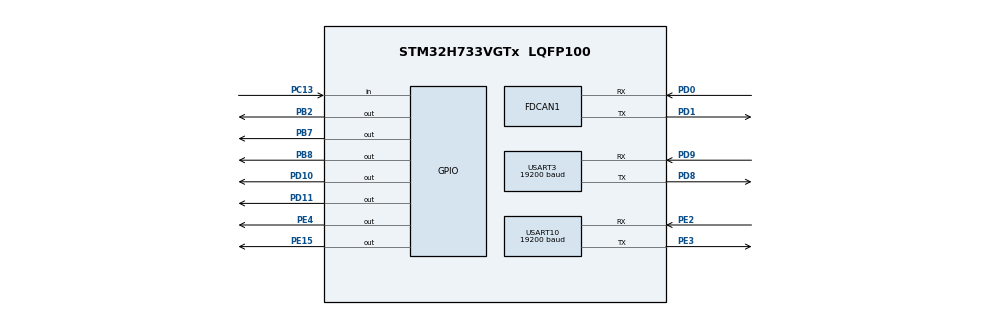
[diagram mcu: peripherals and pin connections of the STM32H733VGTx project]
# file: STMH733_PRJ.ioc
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FDCAN1.NominalPrescaler=6
FDCAN1.NominalTimeSeg1=6
FDCAN1.NominalTimeSeg2=7
Mcu.Family=STM32H7
Mcu.Name=STM32H733VGTx
Mcu.Package=LQFP100
NVIC.FDCAN1_IT0_IRQn=true\:0\:0\:false\:false\:true\:true\:true
NVIC.PriorityGroup=NVIC_PRIORITYGROUP_4
NVIC.TIM1_BRK_IRQn=true\:0\:0\:false\:false\:true\:true\:true
NVIC.TIM1_UP_IRQn=true\:0\:0\:true\:false\:true\:true\:true
NVIC.TIM2_IRQn=true\:0\:0\:false\:false\:true\:true\:true
NVIC.TIM3_IRQn=true\:0\:0\:false\:false\:true\:true\:true
NVIC.TIM8_UP_TIM13_IRQn=true\:0\:0\:false\:false\:true\:true\:true
NVIC.USART10_IRQn=true\:0\:0\:false\:false\:true\:true\:true
NVIC.USART3_IRQn=true\:0\:0\:false\:false\:true\:true\:true
PA13(JTMS/SWDIO).Mode=Serial_Wire
PA13(JTMS/SWDIO).Signal=DEBUG_JTMS-SWDIO
PA14(JTCK/SWCLK).Mode=Serial_Wire
PA14(JTCK/SWCLK).Signal=DEBUG_JTCK-SWCLK
PB2.GPIO_PuPd=GPIO_NOPULL
PB2.Signal=GPIO_Output
PB7.Signal=GPIO_Output
PB8.GPIO_PuPd=GPIO_NOPULL
PB8.Signal=GPIO_Output
PC13.Signal=GPIO_Input
PD0.Mode=FDCAN_Activate
PD0.Signal=FDCAN1_RX
PD1.Mode=FDCAN_Activate
PD1.Signal=FDCAN1_TX
PD10.GPIO_PuPd=GPIO_NOPULL
PD10.GPIO_Speed=GPIO_SPEED_FREQ_VERY_HIGH
PD10.PinState=GPIO_PIN_SET
PD10.Signal=GPIO_Output
PD11.GPIO_PuPd=GPIO_PULLUP
PD11.GPIO_Speed=GPIO_SPEED_FREQ_LOW
PD11.PinState=GPIO_PIN_SET
PD11.Signal=GPIO_Output
PD8.GPIO_ModeDefaultPP=GPIO_MODE_AF_PP
PD8.GPIO_PuPd=GPIO_NOPULL
PD8.GPIO_Speed=GPIO_SPEED_FREQ_VERY_HIGH
PD8.Mode=Asynchronous
PD8.Signal=USART3_TX
PD9.GPIO_ModeDefaultPP=GPIO_MODE_AF_PP
PD9.GPIO_PuPd=GPIO_PULLUP
PD9.GPIO_Speed=GPIO_SPEED_FREQ_VERY_HIGH
PD9.Mode=Asynchronous
PD9.Signal=USART3_RX
PE15.GPIO_PuPd=GPIO_NOPULL
PE15.Signal=GPIO_Output
PE2.GPIO_ModeDefaultPP=GPIO_MODE_AF_PP
PE2.GPIO_PuPd=GPIO_PULLUP
PE2.GPIO_Speed=GPIO_SPEED_FREQ_VERY_HIGH
PE2.Mode=Asynchronous
PE2.Signal=USART10_RX
PE3.GPIO_ModeDefaultPP=GPIO_MODE_AF_PP
PE3.GPIO_PuPd=GPIO_NOPULL
PE3.GPIO_Speed=GPIO_SPEED_FREQ_VERY_HIGH
PE3.Mode=Asynchronous
PE3.Signal=USART10_TX
PE4.GPIO_PuPd=GPIO_PULLDOWN
PE4.Signal=GPIO_Output
PH0-OSC_IN.Mode=HSE-External-Oscillator
PH0-OSC_IN.Signal=RCC_OSC_IN
PH1-OSC_OUT.Mode=HSE-External-Oscillator
PH1-OSC_OUT.Signal=RCC_OSC_OUT
ProjectManager.HeapSize=0x200
ProjectManager.StackSize=0x400
ProjectManager.TargetToolchain=MDK-ARM V5
RCC.ADCFreq_Value=129000000
RCC.APB1Freq_Value=32000000
RCC.APB2Freq_Value=32000000
RCC.APB3Freq_Value=32000000
RCC.APB4Freq_Value=32000000
RCC.CortexFreq_Value=64000000
RCC.D1PPRE=RCC_APB3_DIV2
RCC.D2PPRE1=RCC_APB1_DIV2
RCC.D2PPRE2=RCC_APB2_DIV2
RCC.D3PPRE=RCC_APB4_DIV2
RCC.DIVM1=4
RCC.DIVN1=12
RCC.DIVQ1=4
RCC.HCLKFreq_Value=64000000
RCC.PLLFRACN=0
RCC.SYSCLKFreq_VALUE=64000000
RCC.USBFreq_Value=48000000
TIM1.AutoReloadPreload=TIM_AUTORELOAD_PRELOAD_ENABLE
TIM1.Period=1000-1
TIM1.Prescaler=32-1
TIM13.Period=20*50-1
TIM13.Prescaler=20*32-1
TIM2.Period=50-1
TIM2.Prescaler=32-1
TIM3.Period=49
TIM3.Prescaler=31
USART10.BaudRate=19200
USART10.VirtualMode=VM_ASYNC
USART3.BaudRate=19200
USART3.VirtualMode-Asynchronous=VM_ASYNC
VP_TIM13_VS_ClockSourceINT.Mode=Enable_Timer
VP_TIM1_VS_ClockSourceINT.Mode=Internal
VP_TIM2_VS_ClockSourceINT.Mode=Internal
VP_TIM3_VS_ClockSourceINT.Mode=Internal
board=custom

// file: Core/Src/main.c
/* USER CODE BEGIN Header */
/**
  ******************************************************************************
  * @file           : main.c
  * @brief          : Main program body
  ******************************************************************************
  * @attention
  *
  * <h2><center>&copy; Copyright (c) 2021 STMicroelectronics.
  * All rights reserved.</center></h2>
  *
  * This software component is licensed by ST under BSD 3-Clause license,
  * the "License"; You may not use this file except in compliance with the
  * License. You may obtain a copy of the License at:
  *                        opensource.org/licenses/BSD-3-Clause
  *
  ******************************************************************************
  */
/* USER CODE END Header */
#include "main.h"
#include "fdcan.h"
#include "tim.h"
#include "usart.h"
#include "gpio.h"

/* USER CODE BEGIN Includes */
#include "type.h"
#include "cxpi_driver.h"
/* USER CODE END Includes */

void SystemClock_Config(void);

int main(void)
{

  /* MCU Configuration--------------------------------------------------------*/

  /* Reset of all peripherals, Initializes the Flash interface and the Systick. */
  HAL_Init();

  /* Configure the system clock */
  SystemClock_Config();

  /* Initialize all configured peripherals */
  MX_GPIO_Init();
  MX_TIM2_Init();
  MX_USART3_UART_Init();
  MX_FDCAN1_Init();
  MX_TIM1_Init();
  MX_TIM3_Init();
  MX_USART10_UART_Init();
  MX_TIM13_Init();
  /* USER CODE BEGIN 2 */
	HAL_GPIO_WritePin(GPIOD, GPIO_PIN_11, GPIO_PIN_SET);  //使能引脚将CXPI变为Master模式
	HAL_TIM_Base_Start_IT(&htim2);
	HAL_TIM_Base_Start_IT(&htim1);
	//__HAL_TIM_CLEAR_IT(&htim13,TIM_IT_UPDATE);//清除定时器初始化中的更新中断标志，避免定时器一启动就进入中断
	HAL_TIM_Base_Start_IT(&htim13);
	HAL_GPIO_WritePin((GPIO_TypeDef *)GPIOB, (uint16_t) GPIO_PIN_8,0);//灭灯
  /* USER CODE END 2 */

  /* Infinite loop */
  /* USER CODE BEGIN WHILE */
  while (1)
  {
		//__HAL_TIM_SET_COUNTER(TIM13, 0);
		CXPI_State();
		if(HAL_GPIO_ReadPin(GPIOC,GPIO_PIN_13))//状态1代表按键按下
		{
			HAL_GPIO_TogglePin((GPIO_TypeDef *)GPIOB, (uint16_t) GPIO_PIN_8);//更改红灯状态
			event=1;
			CXPIState=ReceivePTYPE;
			while(HAL_GPIO_ReadPin(GPIOC,GPIO_PIN_13));//等待按键释放
		}
		HAL_GPIO_TogglePin((GPIO_TypeDef *)GPIOB, (uint16_t) GPIO_PIN_2);
		//HAL_GPIO_TogglePin((GPIO_TypeDef *)GPIOB, (uint16_t) GPIO_PIN_8);
		//HAL_Delay(500);
    /* USER CODE END WHILE */

  }
}

void SystemClock_Config(void)
{
  RCC_OscInitTypeDef RCC_OscInitStruct = {0};
  RCC_ClkInitTypeDef RCC_ClkInitStruct = {0};
  RCC_PeriphCLKInitTypeDef PeriphClkInitStruct = {0};

  /** Supply configuration update enable
  */
  HAL_PWREx_ConfigSupply(PWR_LDO_SUPPLY);
  /** Configure the main internal regulator output voltage
  */
  __HAL_PWR_VOLTAGESCALING_CONFIG(PWR_REGULATOR_VOLTAGE_SCALE3);

  while(!__HAL_PWR_GET_FLAG(PWR_FLAG_VOSRDY)) {}
  /** Initializes the RCC Oscillators according to the specified parameters
  * in the RCC_OscInitTypeDef structure.
  */
  RCC_OscInitStruct.OscillatorType = RCC_OSCILLATORTYPE_HSI;
  RCC_OscInitStruct.HSIState = RCC_HSI_DIV1;
  RCC_OscInitStruct.HSICalibrationValue = RCC_HSICALIBRATION_DEFAULT;
  RCC_OscInitStruct.PLL.PLLState = RCC_PLL_ON;
  RCC_OscInitStruct.PLL.PLLSource = RCC_PLLSOURCE_HSI;
  RCC_OscInitStruct.PLL.PLLM = 4;
  RCC_OscInitStruct.PLL.PLLN = 12;
  RCC_OscInitStruct.PLL.PLLP = 2;
  RCC_OscInitStruct.PLL.PLLQ = 4;
  RCC_OscInitStruct.PLL.PLLR = 2;
  RCC_OscInitStruct.PLL.PLLRGE = RCC_PLL1VCIRANGE_3;
  RCC_OscInitStruct.PLL.PLLVCOSEL = RCC_PLL1VCOWIDE;
  RCC_OscInitStruct.PLL.PLLFRACN = 0;
  if (HAL_RCC_OscConfig(&RCC_OscInitStruct) != HAL_OK)
  {
    Error_Handler();
  }
  /** Initializes the CPU, AHB and APB buses clocks
  */
  RCC_ClkInitStruct.ClockType = RCC_CLOCKTYPE_HCLK|RCC_CLOCKTYPE_SYSCLK
                              |RCC_CLOCKTYPE_PCLK1|RCC_CLOCKTYPE_PCLK2
                              |RCC_CLOCKTYPE_D3PCLK1|RCC_CLOCKTYPE_D1PCLK1;
  RCC_ClkInitStruct.SYSCLKSource = RCC_SYSCLKSOURCE_HSI;
  RCC_ClkInitStruct.SYSCLKDivider = RCC_SYSCLK_DIV1;
  RCC_ClkInitStruct.AHBCLKDivider = RCC_HCLK_DIV1;
  RCC_ClkInitStruct.APB3CLKDivider = RCC_APB3_DIV2;
  RCC_ClkInitStruct.APB1CLKDivider = RCC_APB1_DIV2;
  RCC_ClkInitStruct.APB2CLKDivider = RCC_APB2_DIV2;
  RCC_ClkInitStruct.APB4CLKDivider = RCC_APB4_DIV2;

  if (HAL_RCC_ClockConfig(&RCC_ClkInitStruct, FLASH_LATENCY_1) != HAL_OK)
  {
    Error_Handler();
  }
  PeriphClkInitStruct.PeriphClockSelection = RCC_PERIPHCLK_USART3|RCC_PERIPHCLK_FDCAN;
  PeriphClkInitStruct.FdcanClockSelection = RCC_FDCANCLKSOURCE_PLL;
  PeriphClkInitStruct.Usart234578ClockSelection = RCC_USART234578CLKSOURCE_D2PCLK1;
  PeriphClkInitStruct.Usart16ClockSelection = RCC_USART16910CLKSOURCE_D2PCLK2;
  if (HAL_RCCEx_PeriphCLKConfig(&PeriphClkInitStruct) != HAL_OK)
  {
    Error_Handler();
  }
}

void Error_Handler(void)
{
  __disable_irq();
  while (1)
  {
  }
}

/************************ (C) COPYRIGHT STMicroelectronics *****END OF FILE****/
